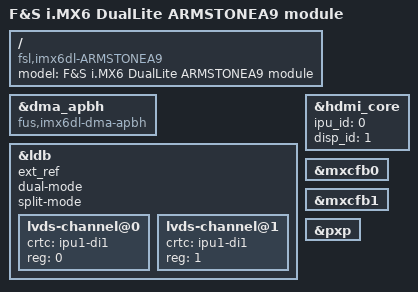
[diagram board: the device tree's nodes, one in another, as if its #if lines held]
/*
 * Copyright (C) 2016 F&S Elektronik Systeme GmbH
 *
 * This program is free software; you can redistribute it and/or modify
 * it under the terms of the GNU General Public License version 2 as
 * published by the Free Software Foundation.
 */

/dts-v1/;

/* The following display config will be converted to Kconfig in the future */
/* Define this if you have at least one display (D0) */
#define CONFIG_ARMSTONEA9_D0
/* Define this if you have a second display (D1) */
#define CONFIG_ARMSTONEA9_D1

/* ENABLE BACKLIGHT LEVELS */
/* enable 16 levels of backlight brightness with correct gamma */
#define CONFIG_ARMSTONEA9_BL_LEVELS_16

/* CONFIGURE DISPLAY 0 */
#ifdef CONFIG_ARMSTONEA9_D0
/* Activate exactly one entry for the type of display D0 */
#define CONFIG_ARMSTONEA9_D0_LCD				// LCD
//#define CONFIG_ARMSTONEA9_D0_LVDS				// LVDS
//#define CONFIG_ARMSTONEA9_D0_HDMI				// HDMI
/*
 * Define a mode_str entry for display D0 (depends on display type above)
 * See the following files for possible values:
 *   LVDS: drivers/video/mxc/ldb.c
 *   LCD:  drivers/video/mxc/mxc_lcdif.c
 *   HDMI: drivers/video/fbdev/mxc/mxc_hdmi.c (actually fetched from panel via EDID)
 */
#ifdef CONFIG_ARMSTONEA9_D0_LCD
	#define CONFIG_ARMSTONEA9_D0_MODE_STR "LCD-ET070080"	// LCD
#elif defined(CONFIG_ARMSTONEA9_D0_LVDS)
	#define CONFIG_ARMSTONEA9_D0_MODE_STR "LDB-WVGA"		// LVDS
#elif defined(CONFIG_ARMSTONEA9_D0_HDMI)
	#define CONFIG_ARMSTONEA9_D0_MODE_STR "1920x1080M@60"	// HDMI
#endif
#endif // CONFIG_ARMSTONEA9_D0

/* CONFIGURE DISPLAY 1 */
#ifdef CONFIG_ARMSTONEA9_D1
/* Activate exactly one entry for the type of display D1 */
//#define CONFIG_ARMSTONEA9_D1_LCD				// LCD
#define CONFIG_ARMSTONEA9_D1_LVDS				// LVDS
//#define CONFIG_ARMSTONEA9_D1_HDMI				// HDMI

/* Define a mode_str entry for display D1 (see comment for D0 above) */
#ifdef CONFIG_ARMSTONEA9_D1_LVDS
	#define CONFIG_ARMSTONEA9_D1_MODE_STR "LDB-WVGA"		// LVDS
#elif defined(CONFIG_ARMSTONEA9_D1_HDMI)
	#define CONFIG_ARMSTONEA9_D1_MODE_STR "1920x1080M@60"	// HDMI
#elif	defined(CONFIG_ARMSTONEA9_D1_LCD)
	#define CONFIG_ARMSTONEA9_D1_MODE_STR "LCD-ET070080"	// LCD
#endif
#endif // CONFIG_ARMSTONEA9_D1

/* CONFIGURE LVDS MULTIDISPLAY*/
/* Two LVDS displays act as two independent displays (with two fb) by default.
   Apart from this  can choose between dual-mode and split-mode */
#if defined(CONFIG_ARMSTONEA9_D0_LVDS) && defined(CONFIG_ARMSTONEA9_D1_LVDS)
/* one LVDS display per channel, one framebuffer for both */
//#define CONFIG_ARMSTONEA9_LVDS_DUAL_MODE
/* two channels for 'split-mode-display', one framebuffer */
//#define CONFIG_ARMSTONEA9_LVDS_SPLIT_MODE
#endif

/* Do some settings to make configurations easier */
#if defined(CONFIG_ARMSTONEA9_D0_LCD) || defined(CONFIG_ARMSTONEA9_D1_LCD)
#define CONFIG_ARMSTONEA9_LCD // activates LCD node
#endif
#if defined(CONFIG_ARMSTONEA9_D0_HDMI) || defined(CONFIG_ARMSTONEA9_D1_HDMI)
#define CONFIG_ARMSTONEA9_HDMI // activates HDMI node
#endif

#if defined(CONFIG_ARMSTONEA9_D0_LVDS) || defined(CONFIG_ARMSTONEA9_D1_LVDS)
#define CONFIG_ARMSTONEA9_LVDS // activates LVDS node
#endif

/* HDMI */
#ifdef CONFIG_ARMSTONEA9_HDMI
#define CONFIG_ARMSTONEA9_HDMI_AUDIO
#endif


/* TOUCH */
/* Please select only one of the following touch devices. Make sure that the
   corresponding touchscreen driver is activated in the kernel */
//#define CONFIG_ARMSTONEA9_4WTOUCH_SX8655_ONBOARD
#define CONFIG_ARMSTONEA9_4WTOUCH_SX8655_RGBADAPTER
//#define CONFIG_ARMSTONEA9_CAPTOUCH_MXT224
//#define CONFIG_ARMSTONEA9_CAPTOUCH_FT5x06

/* NAND */
#define CONFIG_ARMSTONEA9_NAND

/* AUDIO */
#define CONFIG_ARMSTONEA9_SGTL5000_AUDIO

/* Camera connected */
#define CONFIG_ARMSTONEA9_CAMERA_INTERFACE

/* ?? */
//#define CONFIG_ARMSTONEA9_PARALLEL_INTERFACE

/* SERIAL INTERFACE - MIPI CAMERA */
#define CONFIG_ARMSTONEA9_SERIAL_INTERFACE

/* SD-CARD - A is micro SD */
#define CONFIG_ARMSTONEA9_SD_A

/* I2C */
#define CONFIG_ARMSTONEA9_I2C_A
#define CONFIG_ARMSTONEA9_I2C_B
#define CONFIG_ARMSTONEA9_I2C_C

/* SPI */
#define CONFIG_ARMSTONEA9_SPI_A

/* UART */
#define CONFIG_ARMSTONEA9_UART_A
#define CONFIG_ARMSTONEA9_UART_B
#define CONFIG_ARMSTONEA9_UART_C

#include "imx6dl.dtsi"
#include "fsimx6qdl-armstonea9.dtsi"

/ {
	model = "F&S i.MX6 DualLite ARMSTONEA9 module";
	compatible = "fsl,imx6dl-ARMSTONEA9", "fsl,imx6dl";
};

&dma_apbh {
	/* Switch to F&S implementation of APBH DMA driver for GPMI (NAND) */
	compatible = "fus,imx6dl-dma-apbh", "fus,imx28-dma-apbh";
};

#ifdef CONFIG_ARMSTONEA9_LVDS
&ldb {
	ext_ref;
#ifdef CONFIG_ARMSTONEA9_LVDS_DUAL_MODE
	 dual-mode;
#endif
#ifdef CONFIG_ARMSTONEA9_LVDS_SPLIT_MODE
	split-mode;
#endif

#ifdef CONFIG_ARMSTONEA9_LCD		//if LCD is enabled too, LDB uses di1
	lvds-channel@0 {
		crtc = "ipu1-di1"; 	//ipu1-di1 means ipu 0, di1
		reg = <0>;
		status = "okay";
	};
#else
	lvds-channel@0 {		//default LVDS uses di0
		crtc = "ipu1-di0";
		reg = <0>;
		status = "okay";
	};
#endif
#ifdef CONFIG_ARMSTONEA9_D1_LVDS		//if both LVDS channels are used,
	lvds-channel@1 {		//dual and split mode ignore this node
		crtc = "ipu1-di1";
		reg = <1>;
		status = "okay";
	};
#endif
};
#endif

#ifdef CONFIG_ARMSTONEA9_HDMI
&hdmi_core {
	ipu_id = <0>;
	disp_id = <1>;
	status = "okay";
};
#endif

#ifdef CONFIG_ARMSTONEA9_D0
&mxcfb0 {
	status = "okay";
};
#endif

#ifdef CONFIG_ARMSTONEA9_D1
&mxcfb1 {
	status = "okay";
};
#endif

&pxp {
	status = "okay";
};

#if 0
&iomuxc {
	pinctrl-names = "default";
	pinctrl-0 = <&pinctrl_hog_1>, <&pinctrl_hog_2>;

	hog {
		pinctrl_hog_2: hoggrp-2 {
			fsl,pins = <
				/* MAX17135 */
				MX6QDL_PAD_EIM_A17__GPIO2_IO21 0x80000000
				MX6QDL_PAD_EIM_D17__GPIO3_IO17 0x80000000
				MX6QDL_PAD_EIM_D20__GPIO3_IO20 0x80000000
				MX6QDL_PAD_EIM_A18__GPIO2_IO20 0x80000000
				MX6QDL_PAD_EIM_OE__GPIO2_IO25 0x80000000
				/* elan touch */
				MX6QDL_PAD_EIM_A20__GPIO2_IO18 0x80000000
				MX6QDL_PAD_EIM_DA8__GPIO3_IO08 0x80000000
				MX6QDL_PAD_EIM_D28__GPIO3_IO28 0x170b0
			>;
		};
	};
};
#endif
